# STM32WL5X_CM0P register map
File version: 2.1
CPU: CM0 r0p1, little endian, MPU, no FPU, 4 interrupt priority bits
Registers are 32-bit, read-write, reset 0x0 unless marked. A register's access mark holds for its fields unless they carry their own. Offsets are from the block's base; [hi:lo] are bit positions; {n}, {i} and the like mark numbered series; 'fields as' and 'values as' point back to an identical list.

## GPIOC — General-purpose I/Os
Base 0x48000800
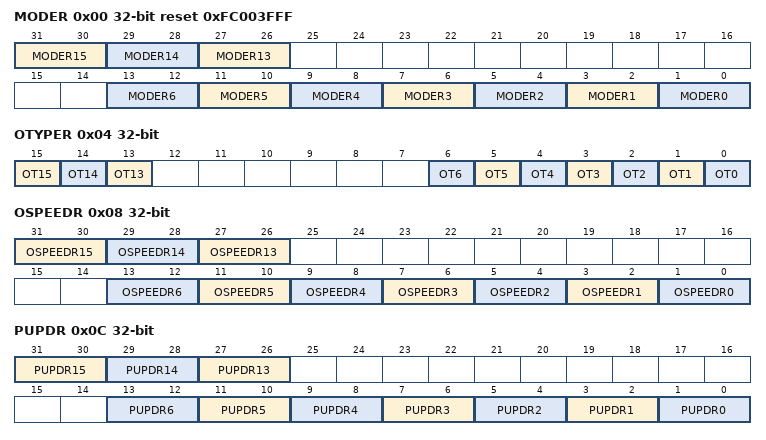
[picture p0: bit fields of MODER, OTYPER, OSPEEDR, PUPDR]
0x00 MODER reset 0xFC003FFF — GPIO port mode register
  [all] fields
    0=Input mode (reset state); 1=Output (General purpose output mode); 2=Alternate function mode; 3=Analog mode
  [31:30] MODER15 — Port x configuration bits (y = 0..15)
  [29:28] MODER14 — Port x configuration bits (y = 0..15)
  [27:26] MODER13 — Port x configuration bits (y = 0..15)
  [2n+1:2n] MODER{n} (n=0..6) — Port x configuration bits (y = 0..15)
0x04 OTYPER — GPIO port output type register
  [all] fields
    0=PushPull (Output push-pull (reset state)); 1=OpenDrain (Output open-drain)
  [15] OT15 — Port x configuration bits (y = 0..15)
  [14] OT14 — Port x configuration bits (y = 0..15)
  [13] OT13 — Port x configuration bits (y = 0..15)
  [n] OT{n} (n=0..6) — Port x configuration bits (y = 0..15)
0x08 OSPEEDR — GPIO port output speed register
  [all] fields
    0=LowSpeed; 1=MediumSpeed; 2=HighSpeed; 3=VeryHighSpeed
  [31:30] OSPEEDR15 — Port x configuration bits (y = 0..15)
  [29:28] OSPEEDR14 — Port x configuration bits (y = 0..15)
  [27:26] OSPEEDR13 — Port x configuration bits (y = 0..15)
  [2n+1:2n] OSPEEDR{n} (n=0..6) — Port x configuration bits (y = 0..15)
0x0C PUPDR — GPIO port pull-up/pull-down register
  [all] fields
    0=Floating (No pull-up, pull-down); 1=PullUp; 2=PullDown
  [31:30] PUPDR15 — Port x configuration bits (y = 0..15)
  [29:28] PUPDR14 — Port x configuration bits (y = 0..15)
  [27:26] PUPDR13 — Port x configuration bits (y = 0..15)
  [2n+1:2n] PUPDR{n} (n=0..6) — Port x configuration bits (y = 0..15)
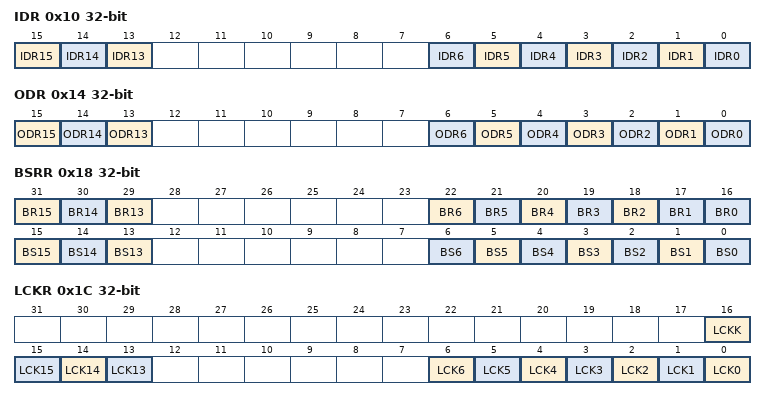
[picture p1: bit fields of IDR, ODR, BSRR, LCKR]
0x10 IDR ro — GPIO port input data register
  [all] fields
    0=Low (Input is logic low); 1=High (Input is logic high)
  [15] IDR15 — Port input data (y = 0..15)
  [14] IDR14 — Port input data (y = 0..15)
  [13] IDR13 — Port input data (y = 0..15)
  [n] IDR{n} (n=0..6) — Port input data (y = 0..15)
0x14 ODR — GPIO port output data register
  [all] fields
    0=Low (Set output to logic low); 1=High (Set output to logic high)
  [15] ODR15 — Port output data (y = 0..15)
  [14] ODR14 — Port output data (y = 0..15)
  [13] ODR13 — Port output data (y = 0..15)
  [n] ODR{n} (n=0..6) — Port output data (y = 0..15)
0x18 BSRR wo — GPIO port bit set/reset register
  [31] BR15 — Port x reset bit y (y = 0..15)
    1=Resets the corresponding ODRx bit
  [30] BR14 — Port x reset bit y (y = 0..15)
    1=Resets the corresponding ODRx bit
  [29] BR13 — Port x reset bit y (y = 0..15)
    1=Resets the corresponding ODRx bit
  [n+16] BR{n} (n=1..6) — Port x reset bit y (y = 0..15)
    1=Resets the corresponding ODRx bit
  [16] BR0 — Port x set bit y (y= 0..15)
    1=Resets the corresponding ODRx bit
  [15] BS15 — Port x set bit y (y= 0..15)
    1=Set (Sets the corresponding ODRx bit)
  [14] BS14 — Port x set bit y (y= 0..15)
    1=Set (Sets the corresponding ODRx bit)
  [13] BS13 — Port x set bit y (y= 0..15)
    1=Set (Sets the corresponding ODRx bit)
  [n] BS{n} (n=0..6) — Port x set bit y (y= 0..15)
    1=Set (Sets the corresponding ODRx bit)
0x1C LCKR — GPIO port configuration lock register
  [16] LCKK — Port x lock bit y (y= 0..15)
    0=NotActive (Port configuration lock key not active); 1=Active (Port configuration lock key active)
  [15] LCK15 — Port x lock bit y (y= 0..15)
    0=Unlocked (Port configuration not locked); 1=Locked (Port configuration locked)
  [14] LCK14 — Port x lock bit y (y= 0..15)
    values as LCK15
  [13] LCK13 — Port x lock bit y (y= 0..15)
    values as LCK15
  [n] LCK{n} (n=0..6) — Port x lock bit y (y= 0..15)
    values as LCK15
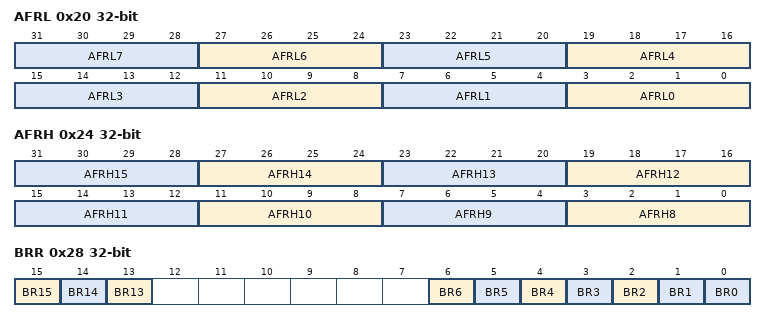
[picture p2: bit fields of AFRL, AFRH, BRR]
0x20 AFRL — GPIO alternate function low register
  [all] fields
    {v}=AF{v} (v=0..15)
  [4n+3:4n] AFRL{n} (n=0..7) — Alternate function selection for port x bit y (y = 0..7)
0x24 AFRH — GPIO alternate function high register
  [all] fields
    {v}=AF{v} (v=0..15)
  [4n-29:4n-32] AFRH{n} (n=8..15) — Alternate function selection for port x bit y (y = 8..15)
0x28 BRR — GPIO port bit reset register
  [15] BR15 — Port Reset bit
    1=Resets the corresponding ODRx bit
  [14] BR14 — Port Reset bit
    1=Resets the corresponding ODRx bit
  [13] BR13 — Port Reset bit
    1=Resets the corresponding ODRx bit
  [n] BR{n} (n=1..6) — Port Reset bit
    1=Resets the corresponding ODRx bit
  [0] BR0 — Port Reset bit
    on write: 0=No action on the corresponding ODx bit; 1=Reset the ODx bit
